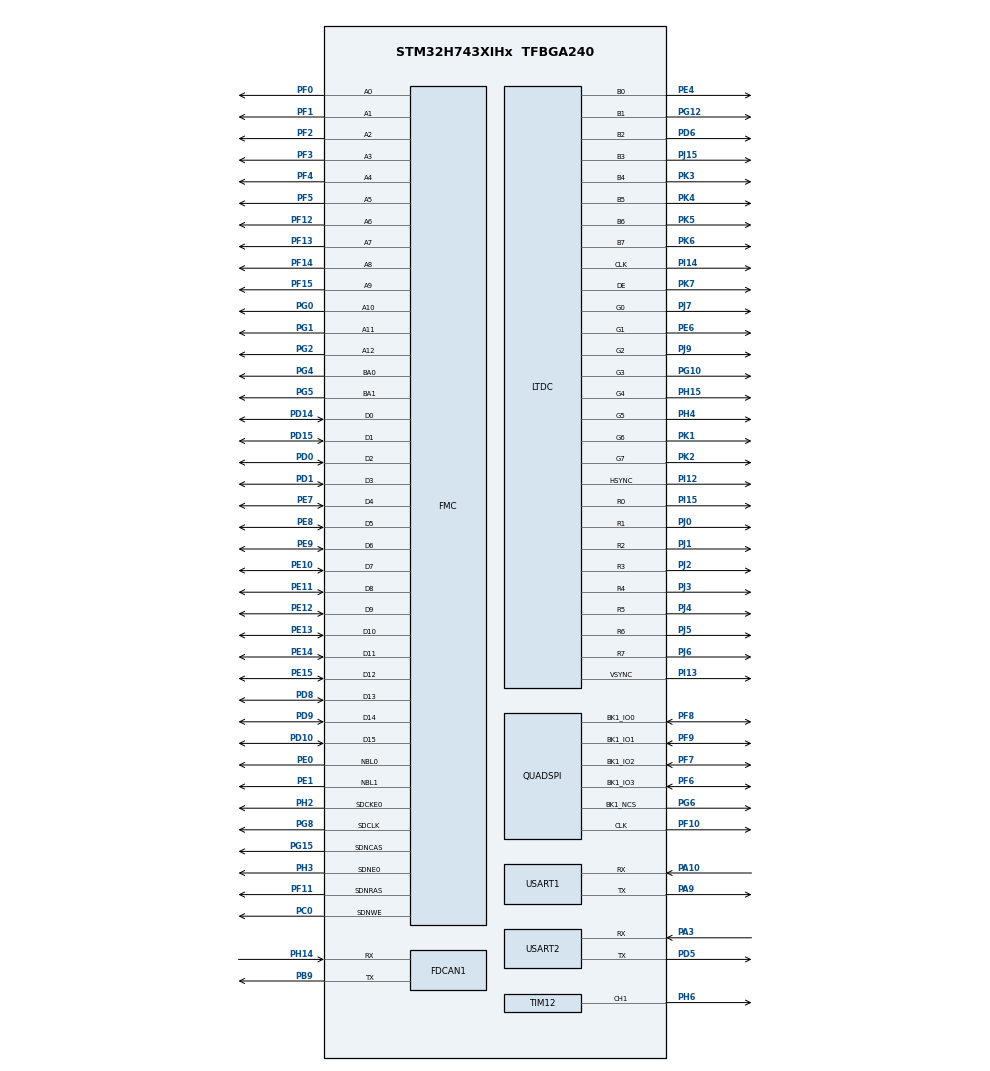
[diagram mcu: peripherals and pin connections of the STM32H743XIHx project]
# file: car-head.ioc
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CORTEX_M7.AccessPermission_Spec=MPU_REGION_FULL_ACCESS
CORTEX_M7.BaseAddress_S-Cortex_Memory_Protection_Unit_Region1_Settings_S=0xC0000000
CORTEX_M7.BaseAddress_Spec=0x90000000
CORTEX_M7.CPU_DCache=Enabled
CORTEX_M7.CPU_ICache=Enabled
CORTEX_M7.DisableExec_Spec=MPU_INSTRUCTION_ACCESS_ENABLE
CORTEX_M7.Enable_S-Cortex_Memory_Protection_Unit_Region1_Settings_S=MPU_REGION_ENABLE
CORTEX_M7.IsBufferable_Spec=MPU_ACCESS_NOT_BUFFERABLE
CORTEX_M7.IsCacheable_S-Cortex_Memory_Protection_Unit_Region1_Settings_S=MPU_ACCESS_CACHEABLE
CORTEX_M7.IsCacheable_Spec=MPU_ACCESS_CACHEABLE
CORTEX_M7.IsShareable_Spec=MPU_ACCESS_NOT_SHAREABLE
CORTEX_M7.Size_S-Cortex_Memory_Protection_Unit_Region1_Settings_S=MPU_REGION_SIZE_32MB
CORTEX_M7.Size_Spec=MPU_REGION_SIZE_256MB
CORTEX_M7.SubRegionDisable_Spec=0x0
CORTEX_M7.default_mode_Activation=1
DMA2D.ColorMode=DMA2D_OUTPUT_RGB565
FDCAN1.AutoRetransmission=ENABLE
FDCAN1.CalculateBaudRateNominal=500000
FDCAN1.CalculateTimeBitNominal=2000
FDCAN1.CalculateTimeQuantumNominal=125.0
FDCAN1.NominalPrescaler=10
FDCAN1.NominalTimeSeg1=13
FDCAN1.NominalTimeSeg2=2
FDCAN1.RxFifo0ElmtsNbr=8
FDCAN1.StdFiltersNbr=1
FDCAN1.TxFifoQueueElmtsNbr=32
FMC.CASLatency1=FMC_SDRAM_CAS_LATENCY_3
FMC.ColumnBitsNumber1=FMC_SDRAM_COLUMN_BITS_NUM_9
FMC.ExitSelfRefreshDelay1=7
FMC.LoadToActiveDelay1=2
FMC.RCDDelay1=2
FMC.RPDelay1=2
FMC.ReadBurst1=FMC_SDRAM_RBURST_ENABLE
FMC.ReadPipeDelay1=FMC_SDRAM_RPIPE_DELAY_1
FMC.RowCycleDelay1=7
FMC.SDClockPeriod1=FMC_SDRAM_CLOCK_PERIOD_2
FMC.SelfRefreshTime1=4
FMC.WriteProtection1=FMC_SDRAM_WRITE_PROTECTION_DISABLE
FMC.WriteRecoveryTime1=3
LTDC.ActiveH=272
LTDC.ActiveW=480
LTDC.Alpha_L0=255
LTDC.FBStartAdress_L0=0xC0000000 
LTDC.HBP=43
LTDC.HFP=8
LTDC.HSync=1
LTDC.ImageHeight_L0=272
LTDC.ImageWidth_L0=480
LTDC.Layers=0
LTDC.PixelFormat_L0=LTDC_PIXEL_FORMAT_RGB565
LTDC.VBP=12
LTDC.VFP=8
LTDC.VSync=1
LTDC.WindowX0_L0=0
LTDC.WindowX1_L0=480
LTDC.WindowY0_L0=0
LTDC.WindowY1_L0=272
Mcu.Family=STM32H7
Mcu.Name=STM32H743XIHx
Mcu.Package=TFBGA240
NVIC.DMA2D_IRQn=true\:0\:0\:false\:false\:true\:true\:true\:true
NVIC.FDCAN1_IT0_IRQn=true\:0\:0\:false\:false\:true\:true\:true\:true
NVIC.FMC_IRQn=true\:0\:0\:false\:false\:true\:true\:true\:true
NVIC.LTDC_ER_IRQn=true\:0\:0\:false\:false\:true\:true\:true\:true
NVIC.LTDC_IRQn=true\:0\:0\:false\:false\:true\:true\:true\:true
NVIC.PriorityGroup=NVIC_PRIORITYGROUP_4
NVIC.TIM7_IRQn=true\:15\:0\:false\:false\:true\:false\:true\:true
NVIC.TimeBase=TIM7_IRQn
NVIC.TimeBaseIP=TIM7
PA10.Mode=Asynchronous
PA10.Signal=USART1_RX
PA13\ (JTMS/SWDIO).Mode=Serial_Wire
PA13\ (JTMS/SWDIO).Signal=DEBUG_JTMS-SWDIO
PA14\ (JTCK/SWCLK).Mode=Serial_Wire
PA14\ (JTCK/SWCLK).Signal=DEBUG_JTCK-SWCLK
PA3.Mode=Asynchronous
PA3.Signal=USART2_RX
PA9.Mode=Asynchronous
PA9.Signal=USART1_TX
PB9.Mode=FDCAN_Activate
PB9.Signal=FDCAN1_TX
PC0.Signal=FMC_SDNWE
PC14-OSC32_IN\ (OSC32_IN).Mode=LSE-External-Oscillator
PC14-OSC32_IN\ (OSC32_IN).Signal=RCC_OSC32_IN
PC15-OSC32_OUT\ (OSC32_OUT).Mode=LSE-External-Oscillator
PC15-OSC32_OUT\ (OSC32_OUT).Signal=RCC_OSC32_OUT
PD0.Signal=FMC_D2_DA2
PD1.Signal=FMC_D3_DA3
PD10.Signal=FMC_D15_DA15
PD14.Signal=FMC_D0_DA0
PD15.Signal=FMC_D1_DA1
PD5.Mode=Asynchronous
PD5.Signal=USART2_TX
PD6.Mode=RGB888
PD6.Signal=LTDC_B2
PD8.Signal=FMC_D13_DA13
PD9.Signal=FMC_D14_DA14
PE0.Signal=FMC_NBL0
PE1.Signal=FMC_NBL1
PE10.Signal=FMC_D7_DA7
PE11.Signal=FMC_D8_DA8
PE12.Signal=FMC_D9_DA9
PE13.Signal=FMC_D10_DA10
PE14.Signal=FMC_D11_DA11
PE15.Signal=FMC_D12_DA12
PE4.Mode=RGB888
PE4.Signal=LTDC_B0
PE6.Mode=RGB888
PE6.Signal=LTDC_G1
PE7.Signal=FMC_D4_DA4
PE8.Signal=FMC_D5_DA5
PE9.Signal=FMC_D6_DA6
PF0.Signal=FMC_A0
PF1.Signal=FMC_A1
PF10.GPIO_Speed=GPIO_SPEED_FREQ_VERY_HIGH
PF10.Mode=Single Bank 1
PF10.Signal=QUADSPI_CLK
PF11.Signal=FMC_SDNRAS
PF12.Signal=FMC_A6
PF13.Signal=FMC_A7
PF14.Signal=FMC_A8
PF15.Signal=FMC_A9
PF2.Signal=FMC_A2
PF3.Signal=FMC_A3
PF4.Signal=FMC_A4
PF5.Signal=FMC_A5
PF6.GPIO_Speed=GPIO_SPEED_FREQ_VERY_HIGH
PF6.Mode=Single Bank 1
PF6.Signal=QUADSPI_BK1_IO3
PF7.GPIO_Speed=GPIO_SPEED_FREQ_VERY_HIGH
PF7.Mode=Single Bank 1
PF7.Signal=QUADSPI_BK1_IO2
PF8.GPIO_Speed=GPIO_SPEED_FREQ_VERY_HIGH
PF8.Mode=Single Bank 1
PF8.Signal=QUADSPI_BK1_IO0
PF9.GPIO_Speed=GPIO_SPEED_FREQ_VERY_HIGH
PF9.Mode=Single Bank 1
PF9.Signal=QUADSPI_BK1_IO1
PG0.Signal=FMC_A10
PG1.Signal=FMC_A11
PG10.GPIO_Speed=GPIO_SPEED_FREQ_VERY_HIGH
PG10.Mode=RGB888
PG10.Signal=LTDC_G3
PG12.Mode=RGB888
PG12.Signal=LTDC_B1
PG15.Signal=FMC_SDNCAS
PG2.Signal=FMC_A12
PG4.Signal=FMC_A14_BA0
PG5.Signal=FMC_A15_BA1
PG6.GPIO_Speed=GPIO_SPEED_FREQ_VERY_HIGH
PG6.Mode=Single Bank 1
PG6.Signal=QUADSPI_BK1_NCS
PG8.Signal=FMC_SDCLK
PH0-OSC_IN\ (PH0).Mode=HSE-External-Oscillator
PH0-OSC_IN\ (PH0).Signal=RCC_OSC_IN
PH1-OSC_OUT\ (PH1).Mode=HSE-External-Oscillator
PH1-OSC_OUT\ (PH1).Signal=RCC_OSC_OUT
PH14.Mode=FDCAN_Activate
PH14.Signal=FDCAN1_RX
PH15.GPIO_Speed=GPIO_SPEED_FREQ_VERY_HIGH
PH15.Mode=RGB888
PH15.Signal=LTDC_G4
PH2.Mode=SdramChipSelect1_1
PH2.Signal=FMC_SDCKE0
PH3.Mode=SdramChipSelect1_1
PH3.Signal=FMC_SDNE0
PH4.GPIO_Speed=GPIO_SPEED_FREQ_VERY_HIGH
PH4.Mode=RGB888
PH4.Signal=LTDC_G5
PH6.Signal=S_TIM12_CH1
PI12.GPIO_Speed=GPIO_SPEED_FREQ_VERY_HIGH
PI12.Mode=RGB888
PI12.Signal=LTDC_HSYNC
PI13.GPIO_Speed=GPIO_SPEED_FREQ_VERY_HIGH
PI13.Mode=RGB888
PI13.Signal=LTDC_VSYNC
PI14.GPIO_Speed=GPIO_SPEED_FREQ_VERY_HIGH
PI14.Mode=RGB888
PI14.Signal=LTDC_CLK
PI15.GPIO_Speed=GPIO_SPEED_FREQ_VERY_HIGH
PI15.Mode=RGB888
PI15.Signal=LTDC_R0
PJ0.GPIO_Speed=GPIO_SPEED_FREQ_VERY_HIGH
PJ0.Mode=RGB888
PJ0.Signal=LTDC_R1
PJ1.GPIO_Speed=GPIO_SPEED_FREQ_VERY_HIGH
PJ1.Mode=RGB888
PJ1.Signal=LTDC_R2
PJ15.GPIO_Speed=GPIO_SPEED_FREQ_VERY_HIGH
PJ15.Mode=RGB888
PJ15.Signal=LTDC_B3
PJ2.GPIO_Speed=GPIO_SPEED_FREQ_VERY_HIGH
PJ2.Mode=RGB888
PJ2.Signal=LTDC_R3
PJ3.GPIO_Speed=GPIO_SPEED_FREQ_VERY_HIGH
PJ3.Mode=RGB888
PJ3.Signal=LTDC_R4
PJ4.GPIO_Speed=GPIO_SPEED_FREQ_VERY_HIGH
PJ4.Mode=RGB888
PJ4.Signal=LTDC_R5
PJ5.GPIO_Speed=GPIO_SPEED_FREQ_VERY_HIGH
PJ5.Mode=RGB888
PJ5.Signal=LTDC_R6
PJ6.GPIO_Speed=GPIO_SPEED_FREQ_VERY_HIGH
PJ6.Mode=RGB888
PJ6.Signal=LTDC_R7
PJ7.GPIO_Speed=GPIO_SPEED_FREQ_VERY_HIGH
PJ7.Mode=RGB888
PJ7.Signal=LTDC_G0
PJ9.GPIO_Speed=GPIO_SPEED_FREQ_VERY_HIGH
PJ9.Mode=RGB888
PJ9.Signal=LTDC_G2
PK1.GPIO_Speed=GPIO_SPEED_FREQ_VERY_HIGH
PK1.Mode=RGB888
PK1.Signal=LTDC_G6
PK2.GPIO_Speed=GPIO_SPEED_FREQ_VERY_HIGH
PK2.Mode=RGB888
PK2.Signal=LTDC_G7
PK3.GPIO_Speed=GPIO_SPEED_FREQ_VERY_HIGH
PK3.Mode=RGB888
PK3.Signal=LTDC_B4
PK4.GPIO_Speed=GPIO_SPEED_FREQ_VERY_HIGH
PK4.Mode=RGB888
PK4.Signal=LTDC_B5
PK5.GPIO_Speed=GPIO_SPEED_FREQ_VERY_HIGH
PK5.Mode=RGB888
PK5.Signal=LTDC_B6
PK6.GPIO_Speed=GPIO_SPEED_FREQ_VERY_HIGH
PK6.Mode=RGB888
PK6.Signal=LTDC_B7
PK7.GPIO_Speed=GPIO_SPEED_FREQ_VERY_HIGH
PK7.Mode=RGB888
PK7.Signal=LTDC_DE
ProjectManager.HeapSize=0x200
ProjectManager.StackSize=0x400
ProjectManager.TargetToolchain=CMake
QUADSPI.ClockMode=QSPI_CLOCK_MODE_3
QUADSPI.ClockPrescaler=1
QUADSPI.FifoThreshold=32
QUADSPI.FlashSize=22
QUADSPI.SampleShifting=QSPI_SAMPLE_SHIFTING_HALFCYCLE
RCC.ADCFreq_Value=75000000
RCC.APB1Freq_Value=120000000
RCC.APB2Freq_Value=120000000
RCC.APB3Freq_Value=120000000
RCC.APB4Freq_Value=120000000
RCC.CortexFreq_Value=480000000
RCC.D1PPRE=RCC_APB3_DIV2
RCC.D2PPRE1=RCC_APB1_DIV2
RCC.D2PPRE2=RCC_APB2_DIV2
RCC.D3PPRE=RCC_APB4_DIV2
RCC.DIVM1=5
RCC.DIVM2=2
RCC.DIVM3=25
RCC.DIVN1=192
RCC.DIVN2=12
RCC.DIVN3=200
RCC.DIVQ1=12
RCC.DIVR3=10
RCC.HCLKFreq_Value=240000000
RCC.HPRE=RCC_HCLK_DIV2
RCC.PLL2FRACN=0
RCC.PLL3FRACN=0
RCC.PLLFRACN=0
RCC.PLLSourceVirtual=RCC_PLLSOURCE_HSE
RCC.SYSCLKFreq_VALUE=480000000
RCC.SYSCLKSource=RCC_SYSCLKSOURCE_PLLCLK
RCC.USBFreq_Value=80000000
SH.FMC_A0.0=FMC_A0,13b-sda1
SH.FMC_A1.0=FMC_A1,13b-sda1
SH.FMC_A10.0=FMC_A10,13b-sda1
SH.FMC_A11.0=FMC_A11,13b-sda1
SH.FMC_A12.0=FMC_A12,13b-sda1
SH.FMC_A14_BA0.0=FMC_BA0,FourSdramBanks1
SH.FMC_A15_BA1.0=FMC_BA1,FourSdramBanks1
SH.FMC_A2.0=FMC_A2,13b-sda1
SH.FMC_A3.0=FMC_A3,13b-sda1
SH.FMC_A4.0=FMC_A4,13b-sda1
SH.FMC_A5.0=FMC_A5,13b-sda1
SH.FMC_A6.0=FMC_A6,13b-sda1
SH.FMC_A7.0=FMC_A7,13b-sda1
SH.FMC_A8.0=FMC_A8,13b-sda1
SH.FMC_A9.0=FMC_A9,13b-sda1
SH.FMC_D0_DA0.0=FMC_D0,sd-16b-d1
SH.FMC_D10_DA10.0=FMC_D10,sd-16b-d1
SH.FMC_D11_DA11.0=FMC_D11,sd-16b-d1
SH.FMC_D12_DA12.0=FMC_D12,sd-16b-d1
SH.FMC_D13_DA13.0=FMC_D13,sd-16b-d1
SH.FMC_D14_DA14.0=FMC_D14,sd-16b-d1
SH.FMC_D15_DA15.0=FMC_D15,sd-16b-d1
SH.FMC_D1_DA1.0=FMC_D1,sd-16b-d1
SH.FMC_D2_DA2.0=FMC_D2,sd-16b-d1
SH.FMC_D3_DA3.0=FMC_D3,sd-16b-d1
SH.FMC_D4_DA4.0=FMC_D4,sd-16b-d1
SH.FMC_D5_DA5.0=FMC_D5,sd-16b-d1
SH.FMC_D6_DA6.0=FMC_D6,sd-16b-d1
SH.FMC_D7_DA7.0=FMC_D7,sd-16b-d1
SH.FMC_D8_DA8.0=FMC_D8,sd-16b-d1
SH.FMC_D9_DA9.0=FMC_D9,sd-16b-d1
SH.FMC_NBL0.0=FMC_NBL0,Sd2ByteEnable1
SH.FMC_NBL1.0=FMC_NBL1,Sd2ByteEnable1
SH.FMC_SDCLK.0=FMC_SDCLK,13b-sda1
SH.FMC_SDNCAS.0=FMC_SDNCAS,13b-sda1
SH.FMC_SDNRAS.0=FMC_SDNRAS,13b-sda1
SH.FMC_SDNWE.0=FMC_SDNWE,13b-sda1
SH.S_TIM12_CH1.0=TIM12_CH1,PWM Generation1 CH1
STMicroelectronics.X-CUBE-TOUCHGFX.4.26.0.ApplicationCcGraphicsJjApplication=TouchGFXOoGenerator
STMicroelectronics.X-CUBE-TOUCHGFX.4.26.0.tgfx_address1=0xC0000000
STMicroelectronics.X-CUBE-TOUCHGFX.4.26.0.tgfx_address2=0xC003FC00
STMicroelectronics.X-CUBE-TOUCHGFX.4.26.0.tgfx_buffering_strategy=Double
STMicroelectronics.X-CUBE-TOUCHGFX.4.26.0.tgfx_display_interface=disp_ltdc
STMicroelectronics.X-CUBE-TOUCHGFX.4.26.0.tgfx_framebuffer_stride=Enabled
STMicroelectronics.X-CUBE-TOUCHGFX.4.26.0.tgfx_hardware_accelerator=dma_2d
STMicroelectronics.X-CUBE-TOUCHGFX.4.26.0.tgfx_location=By Address
STMicroelectronics.X-CUBE-TOUCHGFX.4.26.0.tgfx_vector_fonts=Enabled
STMicroelectronics.X-CUBE-TOUCHGFX.4.26.0.tgfx_vector_rendering=Software
STMicroelectronics.X-CUBE-TOUCHGFX.4.26.0.tgfx_vsync=vsync_ltdc
STMicroelectronics.X-CUBE-TOUCHGFX.4.26.0_IsPackSelfContextualization=true
TIM12.Channel-PWM\ Generation1\ CH1=TIM_CHANNEL_1
TIM12.Period=1000 -1
TIM12.Prescaler=1200
TIM15.Period=0xFFFF
TIM15.Prescaler=240-1
USART1.VirtualMode-Asynchronous=VM_ASYNC
USART2.VirtualMode-Asynchronous=VM_ASYNC
VP_CRC_VS_CRC.Mode=CRC_Activate
VP_DMA2D_VS_DMA2D.Mode=DMA2D_Activate
VP_MEMORYMAP_VS_MEMORYMAP.Mode=CurAppReg
VP_STMicroelectronics.X-CUBE-TOUCHGFX_VS_GraphicsJjApplication_4.26.0.Mode=GraphicsJjApplication
VP_SYS_VS_tim7.Mode=TIM7
VP_TIM15_VS_ClockSourceINT.Mode=Internal
board=custom

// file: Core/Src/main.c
/* USER CODE BEGIN Header */
/**
 ******************************************************************************
 * @file           : main.c
 * @brief          : Main program body
 ******************************************************************************
 * @attention
 *
 * Copyright (c) 2026 STMicroelectronics.
 * All rights reserved.
 *
 * This software is licensed under terms that can be found in the LICENSE file
 * in the root directory of this software component.
 * If no LICENSE file comes with this software, it is provided AS-IS.
 *
 ******************************************************************************
 */
/* USER CODE END Header */
#include "main.h"
#include "crc.h"
#include "dma2d.h"
#include "fdcan.h"
#include "ltdc.h"
#include "quadspi.h"
#include "tim.h"
#include "usart.h"
#include "gpio.h"
#include "fmc.h"
#include "app_touchgfx.h"

/* USER CODE BEGIN Includes */
#include "Bsp_Lcd.h"
#include "Bsp_W25q64.h"
#include <string.h>
#include "data.h"

/* USER CODE END Includes */

void SystemClock_Config(void);
static void MPU_Config(void);
/* USER CODE BEGIN PFP */
static void MPU_Config_SDRAM(void);

/* USER CODE END PFP */

int main(void)
{

  /* MPU Configuration--------------------------------------------------------*/
  MPU_Config();

  /* Enable the CPU Cache */

  /* Enable I-Cache---------------------------------------------------------*/
  SCB_EnableICache();

  /* Enable D-Cache---------------------------------------------------------*/
  SCB_EnableDCache();

  /* MCU Configuration--------------------------------------------------------*/

  /* Reset of all peripherals, Initializes the Flash interface and the Systick. */
  HAL_Init();

  /* USER CODE BEGIN Init */
  MPU_Config_SDRAM();
  /* USER CODE END Init */

  /* Configure the system clock */
  SystemClock_Config();

  /* Initialize all configured peripherals */
  MX_GPIO_Init();
  MX_CRC_Init();
  MX_DMA2D_Init();
  MX_FMC_Init();
  MX_LTDC_Init();
  MX_QUADSPI_Init();
  MX_TIM12_Init();
  MX_TIM15_Init();
  MX_FDCAN1_Init();
  MX_USART1_UART_Init();
  MX_USART2_UART_Init();
  MX_TouchGFX_Init();
  /* USER CODE BEGIN 2 */
  // Test code removed - was overwriting TouchGFX framebuffer
  FDCAN_Filter_Config();

  QSPI_W25Qxx_Init();
  QSPI_W25Qxx_MemoryMappedMode();
  // MX_TouchGFX_Init();
  HAL_TIM_PWM_Start(&TIMER_PWM_CHANNEL, PWM_PIN_CHANNEL);
  Bsp_LcdSetBrightness(1000);
  EC800M_GPS_OPEN();

  /* USER CODE END 2 */

  /* Infinite loop */
  while (1) {

  MX_TouchGFX_Process();
    /* USER CODE BEGIN 3 */

   if (can_data.bodyAirbag == 1 )
  {
    EC800M_Airbagwaring();
  }
  }
  /* USER CODE END 3 */
}

void SystemClock_Config(void)
{
  RCC_OscInitTypeDef RCC_OscInitStruct = {0};
  RCC_ClkInitTypeDef RCC_ClkInitStruct = {0};

  /** Supply configuration update enable
  */
  HAL_PWREx_ConfigSupply(PWR_LDO_SUPPLY);

  /** Configure the main internal regulator output voltage
  */
  __HAL_PWR_VOLTAGESCALING_CONFIG(PWR_REGULATOR_VOLTAGE_SCALE0);

  while(!__HAL_PWR_GET_FLAG(PWR_FLAG_VOSRDY)) {}

  /** Initializes the RCC Oscillators according to the specified parameters
  * in the RCC_OscInitTypeDef structure.
  */
  RCC_OscInitStruct.OscillatorType = RCC_OSCILLATORTYPE_HSE;
  RCC_OscInitStruct.HSEState = RCC_HSE_ON;
  RCC_OscInitStruct.PLL.PLLState = RCC_PLL_ON;
  RCC_OscInitStruct.PLL.PLLSource = RCC_PLLSOURCE_HSE;
  RCC_OscInitStruct.PLL.PLLM = 5;
  RCC_OscInitStruct.PLL.PLLN = 192;
  RCC_OscInitStruct.PLL.PLLP = 2;
  RCC_OscInitStruct.PLL.PLLQ = 12;
  RCC_OscInitStruct.PLL.PLLR = 2;
  RCC_OscInitStruct.PLL.PLLRGE = RCC_PLL1VCIRANGE_2;
  RCC_OscInitStruct.PLL.PLLVCOSEL = RCC_PLL1VCOWIDE;
  RCC_OscInitStruct.PLL.PLLFRACN = 0;
  if (HAL_RCC_OscConfig(&RCC_OscInitStruct) != HAL_OK)
  {
    Error_Handler();
  }

  /** Initializes the CPU, AHB and APB buses clocks
  */
  RCC_ClkInitStruct.ClockType = RCC_CLOCKTYPE_HCLK|RCC_CLOCKTYPE_SYSCLK
                              |RCC_CLOCKTYPE_PCLK1|RCC_CLOCKTYPE_PCLK2
                              |RCC_CLOCKTYPE_D3PCLK1|RCC_CLOCKTYPE_D1PCLK1;
  RCC_ClkInitStruct.SYSCLKSource = RCC_SYSCLKSOURCE_PLLCLK;
  RCC_ClkInitStruct.SYSCLKDivider = RCC_SYSCLK_DIV1;
  RCC_ClkInitStruct.AHBCLKDivider = RCC_HCLK_DIV2;
  RCC_ClkInitStruct.APB3CLKDivider = RCC_APB3_DIV2;
  RCC_ClkInitStruct.APB1CLKDivider = RCC_APB1_DIV2;
  RCC_ClkInitStruct.APB2CLKDivider = RCC_APB2_DIV2;
  RCC_ClkInitStruct.APB4CLKDivider = RCC_APB4_DIV2;

  if (HAL_RCC_ClockConfig(&RCC_ClkInitStruct, FLASH_LATENCY_4) != HAL_OK)
  {
    Error_Handler();
  }
}

/* USER CODE BEGIN 4 */
static void MPU_Config_SDRAM(void) {
  MPU_Region_InitTypeDef MPU_InitStruct = {0};

  MPU_InitStruct.Enable = MPU_REGION_ENABLE;
  MPU_InitStruct.Number = MPU_REGION_NUMBER0;
  MPU_InitStruct.BaseAddress = 0xC0000000;
  MPU_InitStruct.Size = MPU_REGION_SIZE_32MB;
  MPU_InitStruct.SubRegionDisable = 0x0;
  MPU_InitStruct.TypeExtField = MPU_TEX_LEVEL1;
  MPU_InitStruct.AccessPermission = MPU_REGION_FULL_ACCESS;
  MPU_InitStruct.DisableExec = MPU_INSTRUCTION_ACCESS_DISABLE;
  MPU_InitStruct.IsShareable = MPU_ACCESS_NOT_SHAREABLE;
  MPU_InitStruct.IsCacheable = MPU_ACCESS_CACHEABLE;
  MPU_InitStruct.IsBufferable = MPU_ACCESS_BUFFERABLE;
  HAL_MPU_ConfigRegion(&MPU_InitStruct);
}
/* USER CODE END 4 */

 /* MPU Configuration */

void MPU_Config(void)
{
  MPU_Region_InitTypeDef MPU_InitStruct = {0};

  /* Disables the MPU */
  HAL_MPU_Disable();

  /** Initializes and configures the Region and the memory to be protected
  */
  MPU_InitStruct.Enable = MPU_REGION_ENABLE;
  MPU_InitStruct.Number = MPU_REGION_NUMBER0;
  MPU_InitStruct.BaseAddress = 0x90000000;
  MPU_InitStruct.Size = MPU_REGION_SIZE_256MB;
  MPU_InitStruct.SubRegionDisable = 0x0;
  MPU_InitStruct.TypeExtField = MPU_TEX_LEVEL0;
  MPU_InitStruct.AccessPermission = MPU_REGION_FULL_ACCESS;
  MPU_InitStruct.DisableExec = MPU_INSTRUCTION_ACCESS_ENABLE;
  MPU_InitStruct.IsShareable = MPU_ACCESS_NOT_SHAREABLE;
  MPU_InitStruct.IsCacheable = MPU_ACCESS_CACHEABLE;
  MPU_InitStruct.IsBufferable = MPU_ACCESS_NOT_BUFFERABLE;

  HAL_MPU_ConfigRegion(&MPU_InitStruct);

  /** Initializes and configures the Region and the memory to be protected
  */
  MPU_InitStruct.Number = MPU_REGION_NUMBER1;
  MPU_InitStruct.BaseAddress = 0xC0000000;
  MPU_InitStruct.Size = MPU_REGION_SIZE_32MB;
  MPU_InitStruct.AccessPermission = MPU_REGION_NO_ACCESS;

  HAL_MPU_ConfigRegion(&MPU_InitStruct);
  /* Enables the MPU */
  HAL_MPU_Enable(MPU_PRIVILEGED_DEFAULT);

}

void HAL_TIM_PeriodElapsedCallback(TIM_HandleTypeDef *htim)
{
  if (htim->Instance == TIM7)
  {
    HAL_IncTick();
  }
}

void Error_Handler(void)
{
  __disable_irq();
  while (1) {
  }
}
#ifdef USE_FULL_ASSERT
/**
  * @brief  Reports the name of the source file and the source line number
  *         where the assert_param error has occurred.
  * @param  file: pointer to the source file name
  * @param  line: assert_param error line source number
  * @retval None
  */
void assert_failed(uint8_t *file, uint32_t line)
{
  /* USER CODE BEGIN 6 */
  /* User can add his own implementation to report the file name and line
     number, ex: printf("Wrong parameters value: file %s on line %d\r\n", file,
     line) */
  /* USER CODE END 6 */
}
#endif /* USE_FULL_ASSERT */
